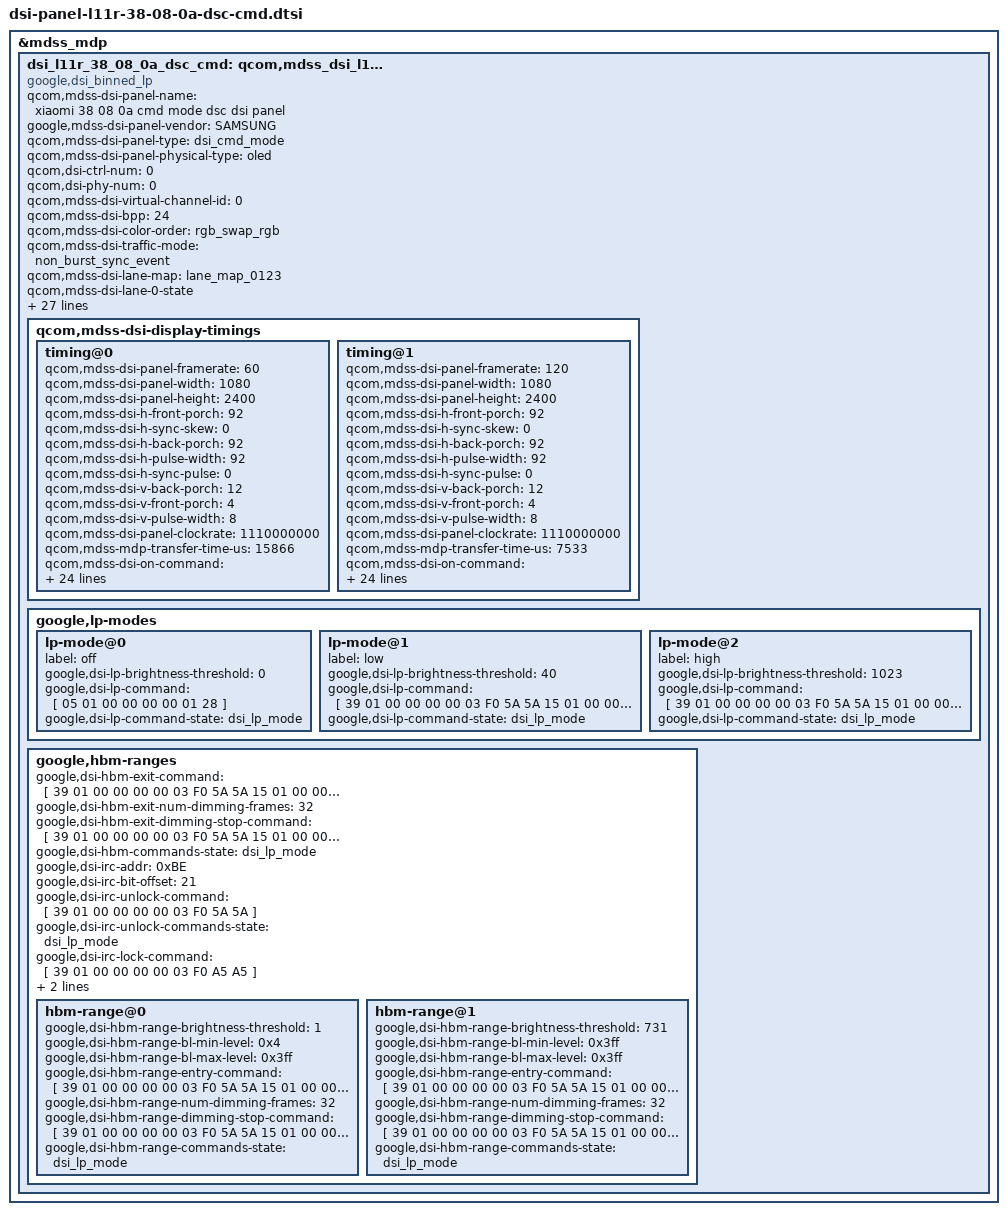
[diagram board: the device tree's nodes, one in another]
// SPDX-License-Identifier: GPL-2.0
/* Copyright (c) 2022, The Linux Foundation. All rights reserved.
 *
 * This program is free software; you can redistribute it and/or modify
 * it under the terms of the GNU General Public License version 2 and
 * only version 2 as published by the Free Software Foundation.
 *
 * This program is distributed in the hope that it will be useful,
 * but WITHOUT ANY WARRANTY; without even the implied warranty of
 * MERCHANTABILITY or FITNESS FOR A PARTICULAR PURPOSE.  See the
 * GNU General Public License for more details.
 */

&mdss_mdp {
	dsi_l11r_38_08_0a_dsc_cmd: qcom,mdss_dsi_l11r_38_08_0a_dsc_cmd {
		compatible = "google,dsi_binned_lp";

		qcom,mdss-dsi-panel-name = "xiaomi 38 08 0a cmd mode dsc dsi panel";
		google,mdss-dsi-panel-vendor = "SAMSUNG";
		qcom,mdss-dsi-panel-type = "dsi_cmd_mode";
		qcom,mdss-dsi-panel-physical-type = "oled";
		qcom,dsi-ctrl-num = <0>;
		qcom,dsi-phy-num = <0>;

		qcom,mdss-dsi-virtual-channel-id = <0>;
		qcom,mdss-dsi-bpp = <24>;
		qcom,mdss-dsi-color-order = "rgb_swap_rgb";
		qcom,mdss-dsi-traffic-mode = "non_burst_sync_event";
		qcom,mdss-dsi-lane-map = "lane_map_0123";
		qcom,mdss-dsi-lane-0-state;
		qcom,mdss-dsi-lane-1-state;
		qcom,mdss-dsi-lane-2-state;
		qcom,mdss-dsi-lane-3-state;

		qcom,mdss-dsi-dma-trigger = "trigger_sw";
		qcom,mdss-dsi-mdp-trigger = "none";
		qcom,mdss-dsi-wr-mem-start = <0x2c>;
		qcom,mdss-dsi-wr-mem-continue = <0x3c>;

		qcom,mdss-dsi-te-pin-select = <1>;
		qcom,mdss-dsi-te-dcs-command = <1>;
		qcom,mdss-dsi-te-check-enable;
		qcom,mdss-dsi-te-using-te-pin;

		qcom,mdss-dsi-bl-pmic-control-type = "bl_ctrl_dcs";
		qcom,mdss-dsi-bl-min-level = <10>;
		qcom,mdss-dsi-bl-max-level = <1023>;
		qcom,mdss-brightness-max-level = <1023>;
		qcom,bl-update-flag = "delay_until_first_frame";
		/* param1 = DBV[9:8], param2 = DBV[7:0] */
		google,dsi-bl-cmd-high-byte-offset = <8>;
		google,dsi-panel-dimming-enable;

		qcom,mdss-dsi-reset-sequence = <0 12>, <1 15>;
		qcom,mdss-dsi-lp11-init;

		qcom,mdss-pan-physical-width-dimension = <70>;
		qcom,mdss-pan-physical-height-dimension = <155>;

		qcom,mdss-dsi-t-clk-post = <0x1F>;
		qcom,mdss-dsi-t-clk-pre = <0x1A>;

		qcom,mdss-dsi-bl-notifier-ranges = <117 199 279 801 1023>;

		qcom,mdss-dsi-display-timings {
			timing@0{
				qcom,mdss-dsi-panel-framerate = <60>;
				qcom,mdss-dsi-panel-width = <1080>;
				qcom,mdss-dsi-panel-height = <2400>;
				qcom,mdss-dsi-h-front-porch = <92>;
				qcom,mdss-dsi-h-sync-skew = <0>;
				qcom,mdss-dsi-h-back-porch = <92>;
				qcom,mdss-dsi-h-pulse-width = <92>;
				qcom,mdss-dsi-h-sync-pulse = <0>;
				qcom,mdss-dsi-v-back-porch = <12>;
				qcom,mdss-dsi-v-front-porch = <4>;
				qcom,mdss-dsi-v-pulse-width = <8>;
				qcom,mdss-dsi-panel-clockrate = <1110000000>;
				qcom,mdss-mdp-transfer-time-us = <15866>;
				qcom,mdss-dsi-on-command = [
					/* DSC Setting */
					39 01 00 00 00 00 02 9D 01				/* Compression Enable */
					39 01 00 00 00 00 81 9E					/* PPS Setting */
					11 00 00 89 30 80 09 60
					04 38 00 1E 02 1C 02 1C
					02 00 02 0E 00 20 02 E3
					00 07 00 0C 03 50 03 64
					18 00 10 F0 03 0C 20 00
					06 0B 0B 33 0E 1C 2A 38
					46 54 62 69 70 77 79 7B
					7D 7E 01 02 01 00 09 40
					09 BE 19 FC 19 FA 19 F8
					1A 38 1A 78 1A B6 2A F6
					2B 34 2B 74 3B 74 6B F4
					00 00 00 00 00 00 00 00
					00 00 00 00 00 00 00 00
					00 00 00 00 00 00 00 00
					00 00 00 00 00 00 00 00
					00 00 00 00 00 00 00 00
					/* Sleep Out, Wait 10 ms */
					05 01 00 00 0A 00 01 11
					/* Set Dimming frames to 8 */
					39 01 00 00 00 00 03 F0 5A 5A
					15 01 00 00 00 00 02 B0 06
					15 01 00 00 00 00 02 B7 08
					/* TE on */
					15 01 00 00 00 00 02 35 00
					/* MIC Setting */
					39 01 00 00 00 00 08 
					DF 00 00 00 01 95 80 0C
					39 01 00 00 00 00 03 F0 A5 A5
					/* Vsync Setting */
					39 01 00 00 00 00 03 F0 5A 5A
					15 01 00 00 00 00 02 B0 01
					15 01 00 00 00 00 02 E6 01
					39 01 00 00 00 00 03 F0 A5 A5
					/* SAP Setting */
					39 01 00 00 00 00 03 F0 5A 5A
					15 01 00 00 00 00 02 B0 03
					39 01 00 00 00 00 03 D4 10 10
					15 01 00 00 00 00 02 F7 03
					39 01 00 00 00 00 03 F0 A5 A5
					/* FFC MIPI Clock Setting */
					39 01 00 00 00 00 03 F0 5A 5A
					39 01 00 00 00 00 03 FC 5A 5A
					15 01 00 00 00 00 02 E9 10
					15 00 00 00 00 00 02 B0 16
					39 00 00 00 00 00 03 D1 2E 1E	/* HFP/RR Setting */
					15 01 00 00 00 00 02 60 00		/* 60HZ Tranzition */
					15 00 00 00 00 00 02 F7 0F		/* Panel Update */
					39 01 00 00 00 00 03 F0 A5 A5
					39 01 00 00 00 00 03 FC A5 A5
					/* CASET/PASET Setting */
					39 01 00 00 00 00 05 2A 00 00 04 37
					39 01 00 00 00 00 05 2B 00 00 09 5F
					/* Sync Setting */
					39 01 00 00 00 00 03 F0 5A 5A
					15 00 00 00 00 00 02 B0 0B
					39 00 00 00 00 00 03 D8 59 70				 	// 0x59 0x70 : 120/60 Hz
					15 00 00 00 00 00 02 F7 0F
					39 01 00 00 00 00 03 F0 A5 A5
					/* Brightness Setting */
					15 01 00 00 6E 00 02 53 28
					05 01 00 00 00 00 01 29
				];
				qcom,mdss-dsi-off-command = [
					05 01 00 00 20 00 01 28       /* display off */
					05 01 00 00 78 00 01 10       /* sleep in */
				];
				qcom,mdss-dsi-on-command-state = "dsi_lp_mode";
				qcom,mdss-dsi-off-command-state = "dsi_lp_mode";

				qcom,mdss-dsi-timing-switch-command = [
					/* write ctl 60hz */
					39 01 00 00 00 00 03 F0 5A 5A
					15 01 00 00 00 00 02 60 00
					15 00 00 00 00 00 02 F7 0F
					39 01 00 00 00 00 03 F0 A5 A5
				];
				qcom,mdss-dsi-timing-switch-command-state = "dsi_lp_mode";

				qcom,mdss-dsi-lp1-command = [
					05 01 00 00 00 00 01 28
					39 01 00 00 00 00 03 F0 5A 5A
					/* HLPM on: 50nit */
					15 01 00 00 00 00 02 60 10
					15 01 00 00 01 00 02 53 22
					15 00 00 00 00 00 02 F7 0F
					39 01 00 00 11 00 03 F0 A5 A5
				];

				qcom,mdss-dsi-nolp-command = [
					05 01 00 00 00 00 01 28
					39 01 00 00 00 00 03 F0 5A 5A
					/* HLPM off */
					15 01 00 00 00 00 02 60 00
					15 01 00 00 01 00 02 53 28
					15 00 00 00 00 00 02 F7 0F
					39 01 00 00 22 00 03 F0 A5 A5
					05 01 00 00 00 00 01 29
				];

				qcom,compression-mode = "dsc";
				qcom,mdss-dsc-slice-height = <8>;
				qcom,mdss-dsc-slice-width = <540>;
				qcom,mdss-dsc-slice-per-pkt = <2>;
				qcom,mdss-dsc-bit-per-component = <8>;
				qcom,mdss-dsc-bit-per-pixel = <8>;
				qcom,mdss-dsc-block-prediction-enable;

				qcom,mdss-dsi-panel-phy-timings = [
					00 25 0A 0A 27 24 0A
					0A 09 02 04 00 1F 1A
				];

				/* 1xLM, 1xDSC Enc, 1xDSI Intf */
				qcom,display-topology = <1 1 1>;
				qcom,default-topology-index = <0>;
			};
			timing@1{
				qcom,mdss-dsi-panel-framerate = <120>;
				qcom,mdss-dsi-panel-width = <1080>;
				qcom,mdss-dsi-panel-height = <2400>;
				qcom,mdss-dsi-h-front-porch = <92>;
				qcom,mdss-dsi-h-sync-skew = <0>;
				qcom,mdss-dsi-h-back-porch = <92>;
				qcom,mdss-dsi-h-pulse-width = <92>;
				qcom,mdss-dsi-h-sync-pulse = <0>;
				qcom,mdss-dsi-v-back-porch = <12>;
				qcom,mdss-dsi-v-front-porch = <4>;
				qcom,mdss-dsi-v-pulse-width = <8>;
				qcom,mdss-dsi-panel-clockrate = <1110000000>;
				qcom,mdss-mdp-transfer-time-us = <7533>;
				qcom,mdss-dsi-on-command = [
					/* DSC Setting */
					39 01 00 00 00 00 02 9D 01				/* Compression Enable */
					39 01 00 00 00 00 81 9E					/* PPS Setting */
					11 00 00 89 30 80 09 60
					04 38 00 1E 02 1C 02 1C
					02 00 02 0E 00 20 02 E3
					00 07 00 0C 03 50 03 64
					18 00 10 F0 03 0C 20 00
					06 0B 0B 33 0E 1C 2A 38
					46 54 62 69 70 77 79 7B
					7D 7E 01 02 01 00 09 40
					09 BE 19 FC 19 FA 19 F8
					1A 38 1A 78 1A B6 2A F6
					2B 34 2B 74 3B 74 6B F4
					00 00 00 00 00 00 00 00
					00 00 00 00 00 00 00 00
					00 00 00 00 00 00 00 00
					00 00 00 00 00 00 00 00
					00 00 00 00 00 00 00 00
					/* Sleep Out, Wait 10 ms */
					05 01 00 00 0A 00 01 11
					/* Set Dimming frames to 8 */
					39 01 00 00 00 00 03 F0 5A 5A
					15 01 00 00 00 00 02 B0 06
					15 01 00 00 00 00 02 B7 08
					/* TE on */
					15 01 00 00 00 00 02 35 00
					/* MIC Setting */
					39 01 00 00 00 00 08 
					DF 00 00 00 01 95 80 0C
					39 01 00 00 00 00 03 F0 A5 A5
					/* Vsync Setting */
					39 01 00 00 00 00 03 F0 5A 5A
					15 01 00 00 00 00 02 B0 01
					15 01 00 00 00 00 02 E6 01
					39 01 00 00 00 00 03 F0 A5 A5
					/* SAP Setting */
					39 01 00 00 00 00 03 F0 5A 5A
					15 01 00 00 00 00 02 B0 03
					39 01 00 00 00 00 03 D4 10 10
					15 01 00 00 00 00 02 F7 03
					39 01 00 00 00 00 03 F0 A5 A5
					/* FFC MIPI Clock Setting */
					39 01 00 00 00 00 03 F0 5A 5A
					39 01 00 00 00 00 03 FC 5A 5A
					15 01 00 00 00 00 02 E9 10
					15 00 00 00 00 00 02 B0 16
					39 00 00 00 00 00 03 D1 2E 1E	/* HFP/RR Setting */
					15 01 00 00 00 00 02 60 10		/* 120HZ Tranzition */
					15 00 00 00 00 00 02 F7 0F		/* Panel Update */
					39 01 00 00 00 00 03 F0 A5 A5
					39 01 00 00 00 00 03 FC A5 A5
					/* CASET/PASET Setting */
					39 01 00 00 00 00 05 2A 00 00 04 37
					39 01 00 00 00 00 05 2B 00 00 09 5F
					/* Sync Setting */
					39 01 00 00 00 00 03 F0 5A 5A
					15 00 00 00 00 00 02 B0 0B
					39 00 00 00 00 00 03 D8 59 70				 	// 0x59 0x70 : 120/60 Hz
					15 00 00 00 00 00 02 F7 0F
					39 01 00 00 00 00 03 F0 A5 A5
					/* Brightness Setting */
					15 01 00 00 6E 00 02 53 28
					05 01 00 00 00 00 01 29
				];
				qcom,mdss-dsi-off-command = [
					05 01 00 00 20 00 01 28       /* display off */
					05 01 00 00 78 00 01 10       /* sleep in */
				];
				qcom,mdss-dsi-on-command-state = "dsi_lp_mode";
				qcom,mdss-dsi-off-command-state = "dsi_lp_mode";

				qcom,mdss-dsi-timing-switch-command = [
					/* write ctl 120hz */
					39 01 00 00 00 00 03 F0 5A 5A
					15 01 00 00 00 00 02 60 10
					15 00 00 00 00 00 02 F7 0F
					39 01 00 00 00 00 03 F0 A5 A5
				];
				qcom,mdss-dsi-timing-switch-command-state = "dsi_lp_mode";

				qcom,mdss-dsi-lp1-command = [
					05 01 00 00 00 00 01 28
					39 01 00 00 00 00 03 F0 5A 5A
					/* HLPM on: 50nit */
					15 01 00 00 00 00 02 60 10
					15 01 00 00 01 00 02 53 22
					15 00 00 00 00 00 02 F7 0F
					39 01 00 00 11 00 03 F0 A5 A5
				];

				qcom,mdss-dsi-nolp-command = [
					05 01 00 00 00 00 01 28
					39 01 00 00 00 00 03 F0 5A 5A
					/* HLPM off */
					15 01 00 00 00 00 02 60 10
					15 01 00 00 01 00 02 53 28
					15 00 00 00 00 00 02 F7 0F
					39 01 00 00 22 00 03 F0 A5 A5
					05 01 00 00 00 00 01 29
				];

				qcom,compression-mode = "dsc";
				qcom,mdss-dsc-slice-height = <8>;
				qcom,mdss-dsc-slice-width = <540>;
				qcom,mdss-dsc-slice-per-pkt = <2>;
				qcom,mdss-dsc-bit-per-component = <8>;
				qcom,mdss-dsc-bit-per-pixel = <8>;
				qcom,mdss-dsc-block-prediction-enable;

				qcom,mdss-dsi-panel-phy-timings = [
					00 25 0A 0A 27 24 0A
					0A 09 02 04 00 1F 1A
				];

				/* 1xLM, 1xDSC Enc, 1xDSI Intf */
				qcom,display-topology = <1 1 1>;
				qcom,default-topology-index = <0>;
			};
		};

		google,lp-modes {
			lp-mode@0 {
				label = "off";
				google,dsi-lp-brightness-threshold = <0>;
				google,dsi-lp-command = [
					/* blank */
					05 01 00 00 00 00 01 28
				];
				google,dsi-lp-command-state = "dsi_lp_mode";
			};

			lp-mode@1 {
				label = "low";
				google,dsi-lp-brightness-threshold = <40>;
				google,dsi-lp-command = [
					39 01 00 00 00 00 03 F0 5A 5A
					/* HLPM on: 50nit */
					15 01 00 00 00 00 02 60 10
					15 01 00 00 01 00 02 53 23
					15 00 00 00 00 00 02 F7 0F
					39 01 00 00 11 00 03 F0 A5 A5
					05 01 00 00 00 00 01 29
				];
				google,dsi-lp-command-state = "dsi_lp_mode";
			};

			lp-mode@2 {
				label = "high";
				google,dsi-lp-brightness-threshold = <1023>;
				google,dsi-lp-command = [
					39 01 00 00 00 00 03 F0 5A 5A
					/* HLPM on: 50nit */
					15 01 00 00 00 00 02 60 10
					15 01 00 00 01 00 02 53 22
					15 00 00 00 00 00 02 F7 0F
					39 01 00 00 11 00 03 F0 A5 A5
					05 01 00 00 00 00 01 29
				];
				google,dsi-lp-command-state = "dsi_lp_mode";
			};
		};

		google,hbm-ranges {
			google,dsi-hbm-exit-command = [
				/* Set Dimming frames to 32 */
				39 01 00 00 00 00 03 F0 5A 5A
				15 01 00 00 00 00 02 B0 06
				15 01 00 00 00 00 02 B7 20
				39 01 00 00 00 00 03 F0 A5 A5

				/* Disable high brightness */
				15 01 00 00 00 00 02 53 28
			];
			google,dsi-hbm-exit-num-dimming-frames = <32>;
			google,dsi-hbm-exit-dimming-stop-command = [
				/* Set Dimming frames to 8 */
				39 01 00 00 00 00 03 F0 5A 5A
				15 01 00 00 00 00 02 B0 06
				15 01 00 00 00 00 02 B7 08
				39 01 00 00 00 00 03 F0 A5 A5
			];
			google,dsi-hbm-commands-state = "dsi_lp_mode";
			google,dsi-irc-addr = <0xBE>;
			google,dsi-irc-bit-offset = <21>;
			google,dsi-irc-unlock-command = [
				39 01 00 00 00 00 03 F0 5A 5A
			];
			google,dsi-irc-unlock-commands-state = "dsi_lp_mode";
			google,dsi-irc-lock-command = [
				39 01 00 00 00 00 03 F0 A5 A5
			];
			google,dsi-irc-lock-commands-state = "dsi_lp_mode";

			hbm-range@0 {
				google,dsi-hbm-range-brightness-threshold = <1>;

				google,dsi-hbm-range-bl-min-level = <0x4>;
				google,dsi-hbm-range-bl-max-level = <0x3ff>;
				google,dsi-hbm-range-entry-command = [
					/* Set Dimming frames to 32 */
					39 01 00 00 00 00 03 F0 5A 5A
					15 01 00 00 00 00 02 B0 06
					15 01 00 00 00 00 02 B7 20
					39 01 00 00 00 00 03 F0 A5 A5

					/* Disable high brightness */
					15 01 00 00 00 00 02 53 28
				];
				google,dsi-hbm-range-num-dimming-frames = <32>;
				google,dsi-hbm-range-dimming-stop-command = [
					/* Set Dimming frames to 8 */
					39 01 00 00 00 00 03 F0 5A 5A
					15 01 00 00 00 00 02 B0 06
					15 01 00 00 00 00 02 B7 08
					39 01 00 00 00 00 03 F0 A5 A5
				];
				google,dsi-hbm-range-commands-state =
					"dsi_lp_mode";
			};

			hbm-range@1 {
				/* Normal brightness mode covers ~2 to 500
				 * nits, using panel brightness values up to
				 * 0x3ff. HBM extends the range to 1300 nits,
				 * and remaps user brightness 1-1023 to cover
				 * this extended range. In this extended range,
				 * 500 nits / 0x3ff corresponds to user
				 * brightness 731. Panel brightness is not
				 * adjustable in the 500-1300 nit segment.
				 */
				google,dsi-hbm-range-brightness-threshold =
					<731>;

				google,dsi-hbm-range-bl-min-level = <0x3ff>;
				google,dsi-hbm-range-bl-max-level = <0x3ff>;

				google,dsi-hbm-range-entry-command = [
					/* Set Dimming frames to 32 */
					39 01 00 00 00 00 03 F0 5A 5A
					15 01 00 00 00 00 02 B0 06
					15 01 00 00 00 00 02 B7 20
					39 01 00 00 00 00 03 F0 A5 A5

					/* Enable high brightness */
					15 01 00 00 00 00 02 53 E8
				];
				google,dsi-hbm-range-num-dimming-frames = <32>;
				google,dsi-hbm-range-dimming-stop-command = [
					/* Set Dimming frames to 8 */
					39 01 00 00 00 00 03 F0 5A 5A
					15 01 00 00 00 00 02 B0 06
					15 01 00 00 00 00 02 B7 08
					39 01 00 00 00 00 03 F0 A5 A5
				];
				google,dsi-hbm-range-commands-state =
					"dsi_lp_mode";
			};
		};
	};
};
